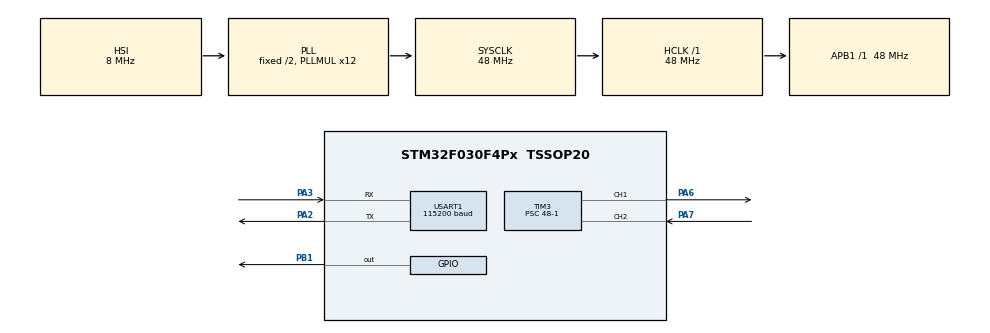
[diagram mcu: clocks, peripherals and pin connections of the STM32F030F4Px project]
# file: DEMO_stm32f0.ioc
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Mcu.Family=STM32F0
Mcu.Name=STM32F030F4Px
Mcu.Package=TSSOP20
NVIC.TIM3_IRQn=true\:0\:0\:false\:false\:true\:true\:true\:true
PA13.Mode=Serial_Wire
PA13.Signal=SYS_SWDIO
PA14.Mode=Serial_Wire
PA14.Signal=SYS_SWCLK
PA2.Mode=Asynchronous
PA2.Signal=USART1_TX
PA3.Mode=Asynchronous
PA3.Signal=USART1_RX
PA6.Signal=S_TIM3_CH1
PA7.Signal=S_TIM3_CH2
PB1.Signal=GPIO_Output
ProjectManager.HeapSize=0x200
ProjectManager.StackSize=0x400
ProjectManager.TargetToolchain=MDK-ARM V5.32
RCC.AHBFreq_Value=48000000
RCC.APB1Freq_Value=48000000
RCC.APB1TimFreq_Value=48000000
RCC.HCLKFreq_Value=48000000
RCC.PLLMUL=RCC_PLL_MUL12
RCC.SYSCLKFreq_VALUE=48000000
RCC.SYSCLKSource=RCC_SYSCLKSOURCE_PLLCLK
SH.S_TIM3_CH1.0=TIM3_CH1,PWM Generation1 CH1
SH.S_TIM3_CH2.0=TIM3_CH2,Input_Capture2_from_TI2
TIM3.Channel-Input_Capture2_from_TI2=TIM_CHANNEL_2
TIM3.Channel-PWM\ Generation1\ CH1=TIM_CHANNEL_1
TIM3.Period=500-1
TIM3.Prescaler=48-1
TIM3.TIM_MasterOutputTrigger=TIM_TRGO_UPDATE
USART1.BaudRate=115200
USART1.VirtualMode-Asynchronous=VM_ASYNC
VP_TIM3_VS_ClockSourceINT.Mode=Internal
board=custom

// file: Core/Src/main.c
/* USER CODE BEGIN Header */
/**
  ******************************************************************************
  * @file           : main.c
  * @brief          : Main program body
  ******************************************************************************
  * @attention
  *
  * Copyright (c) 2022 STMicroelectronics.
  * All rights reserved.
  *
  * This software is licensed under terms that can be found in the LICENSE file
  * in the root directory of this software component.
  * If no LICENSE file comes with this software, it is provided AS-IS.
  *
  ******************************************************************************
  */
/* USER CODE END Header */
#include "main.h"
#include "tim.h"
#include "usart.h"
#include "gpio.h"

/* USER CODE BEGIN Includes */
#include <stdio.h>
/* USER CODE END Includes */

void SystemClock_Config(void);

int main(void)
{

  /* MCU Configuration--------------------------------------------------------*/

  /* Reset of all peripherals, Initializes the Flash interface and the Systick. */
  HAL_Init();

  /* Configure the system clock */
  SystemClock_Config();

  /* Initialize all configured peripherals */
  MX_GPIO_Init();
  MX_TIM3_Init();
  MX_USART1_UART_Init();
  /* USER CODE BEGIN 2 */
  htim3.Instance->CCR1 = 0x7FFF;
  HAL_TIM_IC_Start_IT(&htim3,TIM_CHANNEL_2);//开启输入捕获中断
  HAL_TIM_PWM_Start(&htim3,TIM_CHANNEL_1);//开启CH1 PWM输出
  HAL_TIM_Base_Start_IT(&htim3);
  uint64_t temp_high = 0;
  uint64_t temp_period = 0;
  /* USER CODE END 2 */

  /* Infinite loop */
  while (1)
  {
	  HAL_GPIO_TogglePin(GPIOB,GPIO_PIN_1);
	  if(TIM3CH2_CAPTURE_STA & 0x8000)//如果捕获到高电平
	  {
		  temp_high = TIM3CH2_CAPTURE_STA & 0x3fff;
		  temp_high *= 0xffff;
		  temp_high += TIM3CH2_CAPTURE_VAL;
		  printf("high:%lld us \r\n",temp_high);
		  TIM3CH2_CAPTURE_STA = 0;		//clearerr capture state
	  }
	  if(TIM3CH2_CAPTURE_Period_STA & 0x8000)
	  {
		  temp_period = TIM3CH2_CAPTURE_Period_STA & 0x3fff;
		  temp_period *= 0xffff;
		  temp_period += TIM3CH2_CAPTURE_Period_VAL;
		  printf("period:%lld us \r\n",temp_period);
		  TIM3CH2_CAPTURE_Period_STA = 0;
	  }

    /* USER CODE BEGIN 3 */
	  HAL_Delay(1000);
  }
  /* USER CODE END 3 */
}

void SystemClock_Config(void)
{
  RCC_OscInitTypeDef RCC_OscInitStruct = {0};
  RCC_ClkInitTypeDef RCC_ClkInitStruct = {0};
  RCC_PeriphCLKInitTypeDef PeriphClkInit = {0};

  /** Initializes the RCC Oscillators according to the specified parameters
  * in the RCC_OscInitTypeDef structure.
  */
  RCC_OscInitStruct.OscillatorType = RCC_OSCILLATORTYPE_HSI;
  RCC_OscInitStruct.HSIState = RCC_HSI_ON;
  RCC_OscInitStruct.HSICalibrationValue = RCC_HSICALIBRATION_DEFAULT;
  RCC_OscInitStruct.PLL.PLLState = RCC_PLL_ON;
  RCC_OscInitStruct.PLL.PLLSource = RCC_PLLSOURCE_HSI;
  RCC_OscInitStruct.PLL.PLLMUL = RCC_PLL_MUL12;
  RCC_OscInitStruct.PLL.PREDIV = RCC_PREDIV_DIV1;
  if (HAL_RCC_OscConfig(&RCC_OscInitStruct) != HAL_OK)
  {
    Error_Handler();
  }

  /** Initializes the CPU, AHB and APB buses clocks
  */
  RCC_ClkInitStruct.ClockType = RCC_CLOCKTYPE_HCLK|RCC_CLOCKTYPE_SYSCLK
                              |RCC_CLOCKTYPE_PCLK1;
  RCC_ClkInitStruct.SYSCLKSource = RCC_SYSCLKSOURCE_PLLCLK;
  RCC_ClkInitStruct.AHBCLKDivider = RCC_SYSCLK_DIV1;
  RCC_ClkInitStruct.APB1CLKDivider = RCC_HCLK_DIV1;

  if (HAL_RCC_ClockConfig(&RCC_ClkInitStruct, FLASH_LATENCY_1) != HAL_OK)
  {
    Error_Handler();
  }
  PeriphClkInit.PeriphClockSelection = RCC_PERIPHCLK_USART1;
  PeriphClkInit.Usart1ClockSelection = RCC_USART1CLKSOURCE_PCLK1;
  if (HAL_RCCEx_PeriphCLKConfig(&PeriphClkInit) != HAL_OK)
  {
    Error_Handler();
  }
}

void Error_Handler(void)
{
  __disable_irq();
  while (1)
  {
  }
}
